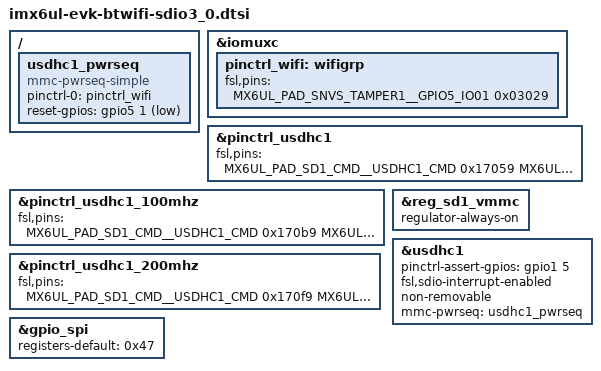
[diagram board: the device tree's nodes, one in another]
// SPDX-License-Identifier: (GPL-2.0+ OR MIT)
/*
 * Copyright 2021 NXP
 */

/*
 * NOTE: This DTS file is written for the wifi chips that supporting 1.8V
 * SDIO3.0, for the wifi chips don't support SDIO3.0, please use the
 * imx6ul-evk-btwifi.dtsi.
 */


/ {
	usdhc1_pwrseq: usdhc1_pwrseq {
		pinctrl-names = "default";
		pinctrl-0 = <&pinctrl_wifi>;
		compatible = "mmc-pwrseq-simple";
		reset-gpios = <&gpio5 1 GPIO_ACTIVE_LOW>;
	};
};

&iomuxc {
	pinctrl_wifi: wifigrp {
		fsl,pins = <
			MX6UL_PAD_SNVS_TAMPER1__GPIO5_IO01 0x03029
		>;
	};
};

&pinctrl_usdhc1 {
	fsl,pins = <
		MX6UL_PAD_SD1_CMD__USDHC1_CMD		0x17059
		MX6UL_PAD_SD1_CLK__USDHC1_CLK		0x10071
		MX6UL_PAD_SD1_DATA0__USDHC1_DATA0	0x17059
		MX6UL_PAD_SD1_DATA1__USDHC1_DATA1	0x17059
		MX6UL_PAD_SD1_DATA2__USDHC1_DATA2	0x17059
		MX6UL_PAD_SD1_DATA3__USDHC1_DATA3	0x17059
		MX6UL_PAD_GPIO1_IO05__GPIO1_IO05	0x17059 /* SD1 VSELECT */
		MX6UL_PAD_GPIO1_IO09__GPIO1_IO09	0x17059 /* SD1 RESET */
	>;
};

&pinctrl_usdhc1_100mhz {
		fsl,pins = <
		MX6UL_PAD_SD1_CMD__USDHC1_CMD		0x170b9
		MX6UL_PAD_SD1_CLK__USDHC1_CLK		0x100b9
		MX6UL_PAD_SD1_DATA0__USDHC1_DATA0	0x170b9
		MX6UL_PAD_SD1_DATA1__USDHC1_DATA1	0x170b9
		MX6UL_PAD_SD1_DATA2__USDHC1_DATA2	0x170b9
		MX6UL_PAD_SD1_DATA3__USDHC1_DATA3	0x170b9
		MX6UL_PAD_GPIO1_IO05__GPIO1_IO05	0x170b9 /* SD1 VSELECT */
		MX6UL_PAD_GPIO1_IO09__GPIO1_IO09	0x170b9 /* SD1 RESET */
	>;
};

&pinctrl_usdhc1_200mhz {
		fsl,pins = <
		MX6UL_PAD_SD1_CMD__USDHC1_CMD		0x170f9
		MX6UL_PAD_SD1_CLK__USDHC1_CLK		0x100f9
		MX6UL_PAD_SD1_DATA0__USDHC1_DATA0	0x170f9
		MX6UL_PAD_SD1_DATA1__USDHC1_DATA1	0x170f9
		MX6UL_PAD_SD1_DATA2__USDHC1_DATA2	0x170f9
		MX6UL_PAD_SD1_DATA3__USDHC1_DATA3	0x170f9
		MX6UL_PAD_GPIO1_IO05__GPIO1_IO05	0x170f9 /* SD1 VSELECT */
		MX6UL_PAD_GPIO1_IO09__GPIO1_IO09	0x170f9 /* SD1 RESET */
	>;
};

&reg_sd1_vmmc {
	regulator-always-on;
};

&usdhc1 {
	#address-cells = <1>;
	#size-cells = <0>;
	pinctrl-assert-gpios = <&gpio1 5 GPIO_ACTIVE_HIGH>;
	fsl,sdio-interrupt-enabled;
	non-removable;
	mmc-pwrseq = <&usdhc1_pwrseq>;
	/delete-property/ enable-sdio-wakeup;
	/delete-property/ cd-gpios;
};

&gpio_spi {
	/* Murata: modify default setting so that BT_nPWD/BT_REG_ON
	 * is low (0V) during kernel boot.
	 */
	registers-default = /bits/ 8 <0x47>;
};
